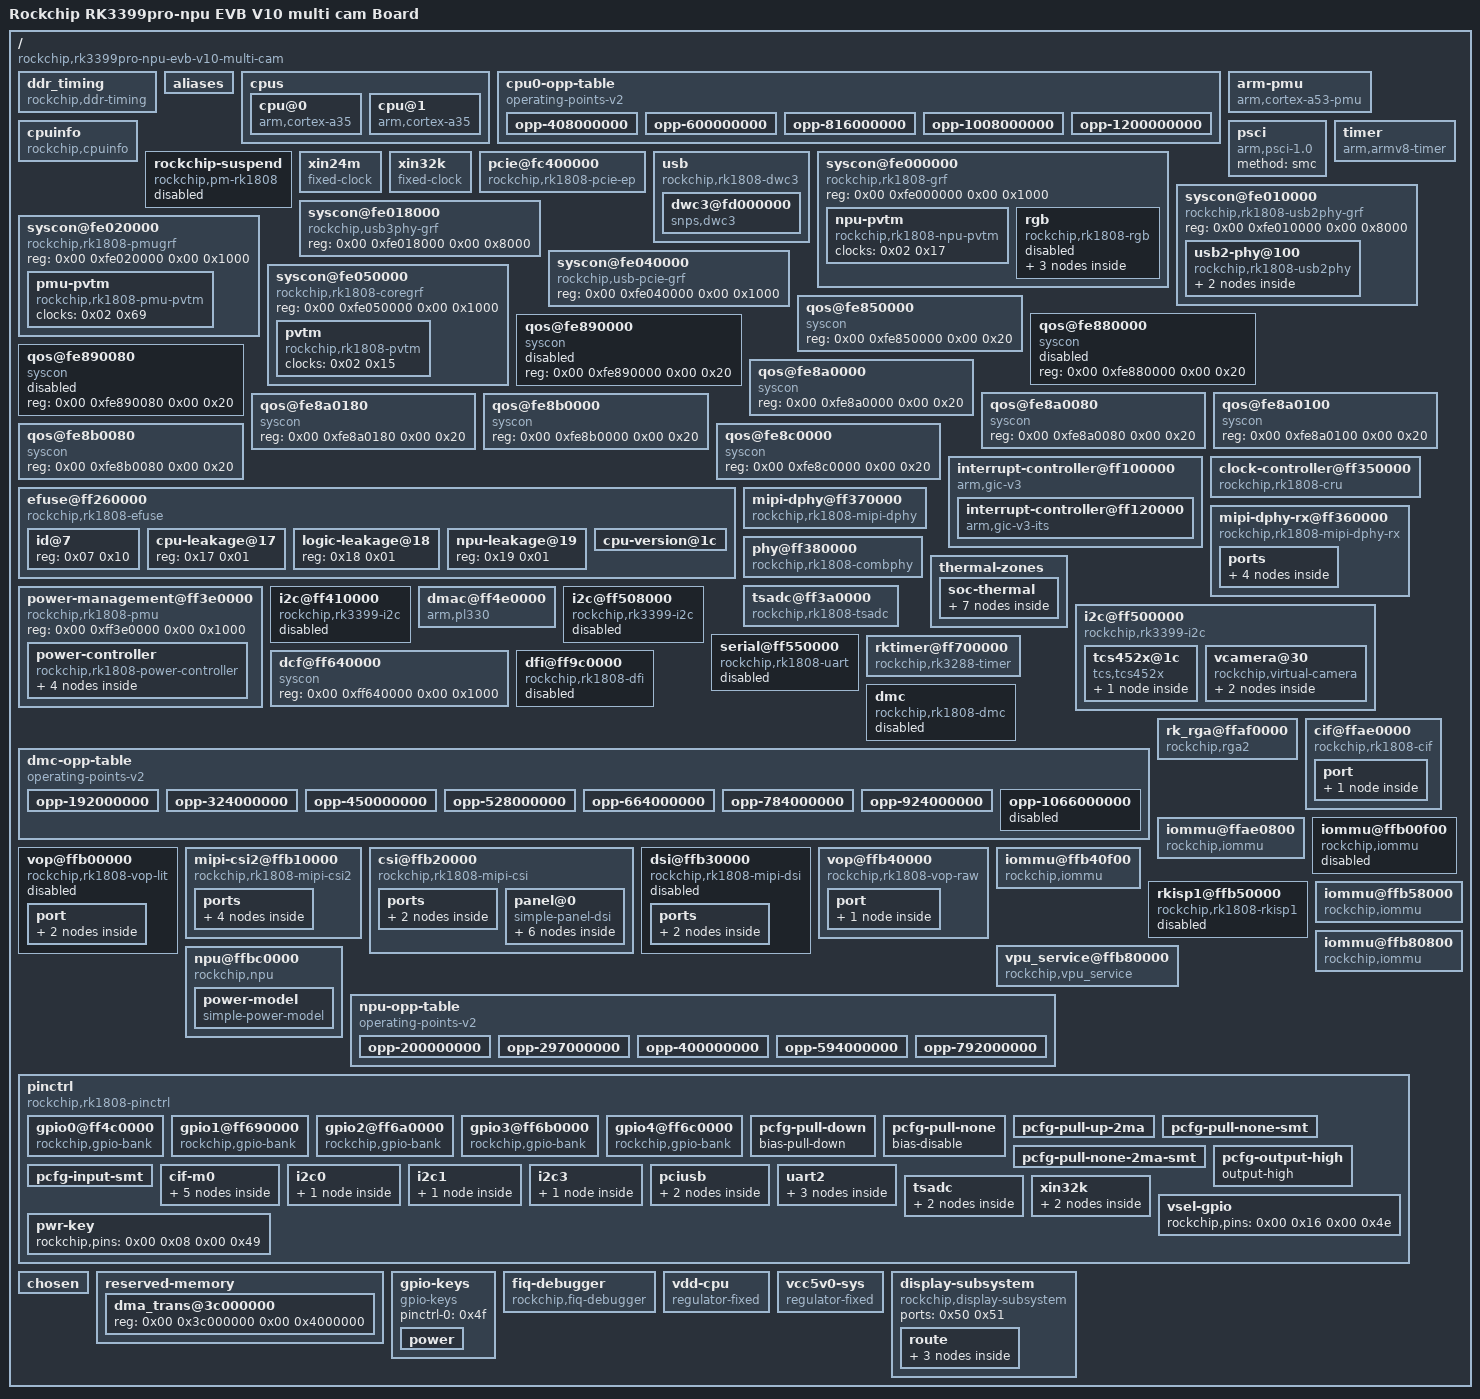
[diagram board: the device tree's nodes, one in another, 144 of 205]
/dts-v1/;

/ {
	compatible = "rockchip,rk3399pro-npu-evb-v10-multi-cam\0rockchip,rk3399pro-npu";
	interrupt-parent = <0x01>;
	#address-cells = <0x02>;
	#size-cells = <0x02>;
	model = "Rockchip RK3399pro-npu EVB V10 multi cam Board";

	ddr_timing {
		compatible = "rockchip,ddr-timing";
		ddr2_speed_bin = <0x00>;
		ddr3_speed_bin = <0x15>;
		ddr4_speed_bin = <0x0c>;
		pd_idle = <0x00>;
		sr_idle = <0x00>;
		sr_mc_gate_idle = <0x00>;
		srpd_lite_idle = <0x00>;
		standby_idle = <0x00>;
		auto_pd_dis_freq = <0x42a>;
		auto_sr_dis_freq = <0x320>;
		ddr2_dll_dis_freq = <0x12c>;
		ddr3_dll_dis_freq = <0x12c>;
		ddr4_dll_dis_freq = <0x271>;
		phy_dll_dis_freq = <0x190>;
		ddr2_odt_dis_freq = <0x64>;
		phy_ddr2_odt_dis_freq = <0x64>;
		ddr2_drv = <0x01>;
		ddr2_odt = <0x96>;
		phy_ddr2_ca_drv = <0x12>;
		phy_ddr2_ck_drv = <0x10>;
		phy_ddr2_dq_drv = <0x12>;
		phy_ddr2_odt = <0x04>;
		ddr3_odt_dis_freq = <0x190>;
		phy_ddr3_odt_dis_freq = <0x190>;
		ddr3_drv = <0x28>;
		ddr3_odt = <0x78>;
		phy_ddr3_ca_drv = <0x12>;
		phy_ddr3_ck_drv = <0x10>;
		phy_ddr3_dq_drv = <0x12>;
		phy_ddr3_odt = <0x04>;
		phy_lpddr2_odt_dis_freq = <0x29a>;
		lpddr2_drv = <0x28>;
		phy_lpddr2_ca_drv = <0x13>;
		phy_lpddr2_ck_drv = <0x11>;
		phy_lpddr2_dq_drv = <0x13>;
		phy_lpddr2_odt = <0x00>;
		lpddr3_odt_dis_freq = <0x190>;
		phy_lpddr3_odt_dis_freq = <0x190>;
		lpddr3_drv = <0x28>;
		lpddr3_odt = <0xf0>;
		phy_lpddr3_ca_drv = <0x13>;
		phy_lpddr3_ck_drv = <0x11>;
		phy_lpddr3_dq_drv = <0x13>;
		phy_lpddr3_odt = <0x04>;
		lpddr4_odt_dis_freq = <0x320>;
		phy_lpddr4_odt_dis_freq = <0x320>;
		lpddr4_drv = <0x3c>;
		lpddr4_dq_odt = <0x28>;
		lpddr4_ca_odt = <0x28>;
		phy_lpddr4_ca_drv = <0x11>;
		phy_lpddr4_ck_cs_drv = <0x05>;
		phy_lpddr4_dq_drv = <0x05>;
		phy_lpddr4_odt = <0x19>;
		ddr4_odt_dis_freq = <0x29a>;
		phy_ddr4_odt_dis_freq = <0x29a>;
		ddr4_drv = <0x22>;
		ddr4_odt = <0xf0>;
		phy_ddr4_ca_drv = <0x13>;
		phy_ddr4_ck_drv = <0x11>;
		phy_ddr4_dq_drv = <0x13>;
		phy_ddr4_odt = <0x04>;
		a0_ddr3a9_de-skew = <0x07>;
		a1_ddr3a14_de-skew = <0x07>;
		a2_ddr3a13_de-skew = <0x07>;
		a3_ddr3a11_de-skew = <0x07>;
		a4_ddr3a2_de-skew = <0x07>;
		a5_ddr3a4_de-skew = <0x07>;
		a6_ddr3a3_de-skew = <0x07>;
		a7_ddr3a6_de-skew = <0x07>;
		a8_ddr3a5_de-skew = <0x07>;
		a9_ddr3a1_de-skew = <0x07>;
		a10_ddr3a0_de-skew = <0x07>;
		a11_ddr3a7_de-skew = <0x07>;
		a12_ddr3casb_de-skew = <0x07>;
		a13_ddr3a8_de-skew = <0x07>;
		a14_ddr3odt0_de-skew = <0x07>;
		a15_ddr3ba1_de-skew = <0x07>;
		a16_ddr3rasb_de-skew = <0x07>;
		a17_ddr3null_de-skew = <0x07>;
		ba0_ddr3ba2_de-skew = <0x07>;
		ba1_ddr3a12_de-skew = <0x07>;
		bg0_ddr3ba0_de-skew = <0x07>;
		bg1_ddr3web_de-skew = <0x07>;
		cke_ddr3cke_de-skew = <0x07>;
		ck_ddr3ck_de-skew = <0x07>;
		ckb_ddr3ckb_de-skew = <0x07>;
		csb0_ddr3a10_de-skew = <0x07>;
		odt0_ddr3a15_de-skew = <0x07>;
		resetn_ddr3resetn_de-skew = <0x07>;
		actn_ddr3csb0_de-skew = <0x07>;
		csb1_ddr3csb1_de-skew = <0x07>;
		odt1_ddr3odt1_de-skew = <0x07>;
		cs0_dm0_rx_de-skew = <0x07>;
		cs0_dm0_tx_de-skew = <0x07>;
		cs0_dq0_rx_de-skew = <0x07>;
		cs0_dq0_tx_de-skew = <0x07>;
		cs0_dq1_rx_de-skew = <0x07>;
		cs0_dq1_tx_de-skew = <0x07>;
		cs0_dq2_rx_de-skew = <0x07>;
		cs0_dq2_tx_de-skew = <0x07>;
		cs0_dq3_rx_de-skew = <0x07>;
		cs0_dq3_tx_de-skew = <0x07>;
		cs0_dq4_rx_de-skew = <0x07>;
		cs0_dq4_tx_de-skew = <0x07>;
		cs0_dq5_rx_de-skew = <0x07>;
		cs0_dq5_tx_de-skew = <0x07>;
		cs0_dq6_rx_de-skew = <0x07>;
		cs0_dq6_tx_de-skew = <0x07>;
		cs0_dq7_rx_de-skew = <0x07>;
		cs0_dq7_tx_de-skew = <0x07>;
		cs0_dqs0p_rx_de-skew = <0x0e>;
		cs0_dqs0p_tx_de-skew = <0x09>;
		cs0_dqs0n_tx_de-skew = <0x09>;
		cs0_dm1_rx_de-skew = <0x07>;
		cs0_dm1_tx_de-skew = <0x07>;
		cs0_dq8_rx_de-skew = <0x07>;
		cs0_dq8_tx_de-skew = <0x07>;
		cs0_dq9_rx_de-skew = <0x07>;
		cs0_dq9_tx_de-skew = <0x07>;
		cs0_dq10_rx_de-skew = <0x07>;
		cs0_dq10_tx_de-skew = <0x07>;
		cs0_dq11_rx_de-skew = <0x07>;
		cs0_dq11_tx_de-skew = <0x07>;
		cs0_dq12_rx_de-skew = <0x07>;
		cs0_dq12_tx_de-skew = <0x07>;
		cs0_dq13_rx_de-skew = <0x07>;
		cs0_dq13_tx_de-skew = <0x07>;
		cs0_dq14_rx_de-skew = <0x07>;
		cs0_dq14_tx_de-skew = <0x07>;
		cs0_dq15_rx_de-skew = <0x07>;
		cs0_dq15_tx_de-skew = <0x07>;
		cs0_dqs1p_rx_de-skew = <0x0e>;
		cs0_dqs1p_tx_de-skew = <0x09>;
		cs0_dqs1n_tx_de-skew = <0x09>;
		cs0_dqs0n_rx_de-skew = <0x0e>;
		cs0_dqs1n_rx_de-skew = <0x0e>;
		cs0_dm2_rx_de-skew = <0x07>;
		cs0_dm2_tx_de-skew = <0x07>;
		cs0_dq16_rx_de-skew = <0x07>;
		cs0_dq16_tx_de-skew = <0x07>;
		cs0_dq17_rx_de-skew = <0x07>;
		cs0_dq17_tx_de-skew = <0x07>;
		cs0_dq18_rx_de-skew = <0x07>;
		cs0_dq18_tx_de-skew = <0x07>;
		cs0_dq19_rx_de-skew = <0x07>;
		cs0_dq19_tx_de-skew = <0x07>;
		cs0_dq20_rx_de-skew = <0x07>;
		cs0_dq20_tx_de-skew = <0x07>;
		cs0_dq21_rx_de-skew = <0x07>;
		cs0_dq21_tx_de-skew = <0x07>;
		cs0_dq22_rx_de-skew = <0x07>;
		cs0_dq22_tx_de-skew = <0x07>;
		cs0_dq23_rx_de-skew = <0x07>;
		cs0_dq23_tx_de-skew = <0x07>;
		cs0_dqs2p_rx_de-skew = <0x0e>;
		cs0_dqs2p_tx_de-skew = <0x09>;
		cs0_dqs2n_tx_de-skew = <0x09>;
		cs0_dm3_rx_de-skew = <0x07>;
		cs0_dm3_tx_de-skew = <0x07>;
		cs0_dq24_rx_de-skew = <0x07>;
		cs0_dq24_tx_de-skew = <0x07>;
		cs0_dq25_rx_de-skew = <0x07>;
		cs0_dq25_tx_de-skew = <0x07>;
		cs0_dq26_rx_de-skew = <0x07>;
		cs0_dq26_tx_de-skew = <0x07>;
		cs0_dq27_rx_de-skew = <0x07>;
		cs0_dq27_tx_de-skew = <0x07>;
		cs0_dq28_rx_de-skew = <0x07>;
		cs0_dq28_tx_de-skew = <0x07>;
		cs0_dq29_rx_de-skew = <0x07>;
		cs0_dq29_tx_de-skew = <0x07>;
		cs0_dq30_rx_de-skew = <0x07>;
		cs0_dq30_tx_de-skew = <0x07>;
		cs0_dq31_rx_de-skew = <0x07>;
		cs0_dq31_tx_de-skew = <0x07>;
		cs0_dqs3p_rx_de-skew = <0x0e>;
		cs0_dqs3p_tx_de-skew = <0x09>;
		cs0_dqs3n_tx_de-skew = <0x09>;
		cs0_dqs2n_rx_de-skew = <0x0e>;
		cs0_dqs3n_rx_de-skew = <0x0e>;
		cs1_dm0_rx_de-skew = <0x07>;
		cs1_dm0_tx_de-skew = <0x07>;
		cs1_dq0_rx_de-skew = <0x07>;
		cs1_dq0_tx_de-skew = <0x07>;
		cs1_dq1_rx_de-skew = <0x07>;
		cs1_dq1_tx_de-skew = <0x07>;
		cs1_dq2_rx_de-skew = <0x07>;
		cs1_dq2_tx_de-skew = <0x07>;
		cs1_dq3_rx_de-skew = <0x07>;
		cs1_dq3_tx_de-skew = <0x07>;
		cs1_dq4_rx_de-skew = <0x07>;
		cs1_dq4_tx_de-skew = <0x07>;
		cs1_dq5_rx_de-skew = <0x07>;
		cs1_dq5_tx_de-skew = <0x07>;
		cs1_dq6_rx_de-skew = <0x07>;
		cs1_dq6_tx_de-skew = <0x07>;
		cs1_dq7_rx_de-skew = <0x07>;
		cs1_dq7_tx_de-skew = <0x07>;
		cs1_dqs0p_rx_de-skew = <0x0e>;
		cs1_dqs0p_tx_de-skew = <0x09>;
		cs1_dqs0n_tx_de-skew = <0x09>;
		cs1_dm1_rx_de-skew = <0x07>;
		cs1_dm1_tx_de-skew = <0x07>;
		cs1_dq8_rx_de-skew = <0x07>;
		cs1_dq8_tx_de-skew = <0x07>;
		cs1_dq9_rx_de-skew = <0x07>;
		cs1_dq9_tx_de-skew = <0x07>;
		cs1_dq10_rx_de-skew = <0x07>;
		cs1_dq10_tx_de-skew = <0x07>;
		cs1_dq11_rx_de-skew = <0x07>;
		cs1_dq11_tx_de-skew = <0x07>;
		cs1_dq12_rx_de-skew = <0x07>;
		cs1_dq12_tx_de-skew = <0x07>;
		cs1_dq13_rx_de-skew = <0x07>;
		cs1_dq13_tx_de-skew = <0x07>;
		cs1_dq14_rx_de-skew = <0x07>;
		cs1_dq14_tx_de-skew = <0x07>;
		cs1_dq15_rx_de-skew = <0x07>;
		cs1_dq15_tx_de-skew = <0x07>;
		cs1_dqs1p_rx_de-skew = <0x0e>;
		cs1_dqs1p_tx_de-skew = <0x09>;
		cs1_dqs1n_tx_de-skew = <0x09>;
		cs1_dqs0n_rx_de-skew = <0x0e>;
		cs1_dqs1n_rx_de-skew = <0x0e>;
		cs1_dm2_rx_de-skew = <0x07>;
		cs1_dm2_tx_de-skew = <0x07>;
		cs1_dq16_rx_de-skew = <0x07>;
		cs1_dq16_tx_de-skew = <0x07>;
		cs1_dq17_rx_de-skew = <0x07>;
		cs1_dq17_tx_de-skew = <0x07>;
		cs1_dq18_rx_de-skew = <0x07>;
		cs1_dq18_tx_de-skew = <0x07>;
		cs1_dq19_rx_de-skew = <0x07>;
		cs1_dq19_tx_de-skew = <0x07>;
		cs1_dq20_rx_de-skew = <0x07>;
		cs1_dq20_tx_de-skew = <0x07>;
		cs1_dq21_rx_de-skew = <0x07>;
		cs1_dq21_tx_de-skew = <0x07>;
		cs1_dq22_rx_de-skew = <0x07>;
		cs1_dq22_tx_de-skew = <0x07>;
		cs1_dq23_rx_de-skew = <0x07>;
		cs1_dq23_tx_de-skew = <0x07>;
		cs1_dqs2p_rx_de-skew = <0x0e>;
		cs1_dqs2p_tx_de-skew = <0x09>;
		cs1_dqs2n_tx_de-skew = <0x09>;
		cs1_dm3_rx_de-skew = <0x07>;
		cs1_dm3_tx_de-skew = <0x07>;
		cs1_dq24_rx_de-skew = <0x07>;
		cs1_dq24_tx_de-skew = <0x07>;
		cs1_dq25_rx_de-skew = <0x07>;
		cs1_dq25_tx_de-skew = <0x07>;
		cs1_dq26_rx_de-skew = <0x07>;
		cs1_dq26_tx_de-skew = <0x07>;
		cs1_dq27_rx_de-skew = <0x07>;
		cs1_dq27_tx_de-skew = <0x07>;
		cs1_dq28_rx_de-skew = <0x07>;
		cs1_dq28_tx_de-skew = <0x07>;
		cs1_dq29_rx_de-skew = <0x07>;
		cs1_dq29_tx_de-skew = <0x07>;
		cs1_dq30_rx_de-skew = <0x07>;
		cs1_dq30_tx_de-skew = <0x07>;
		cs1_dq31_rx_de-skew = <0x07>;
		cs1_dq31_tx_de-skew = <0x07>;
		cs1_dqs3p_rx_de-skew = <0x0e>;
		cs1_dqs3p_tx_de-skew = <0x09>;
		cs1_dqs3n_tx_de-skew = <0x09>;
		cs1_dqs2n_rx_de-skew = <0x0e>;
		cs1_dqs3n_rx_de-skew = <0x0e>;
		phandle = <0x35>;
	};

	aliases {
		i2c0 = "/i2c@ff410000";
		i2c1 = "/i2c@ff500000";
		i2c3 = "/i2c@ff508000";
		serial2 = "/serial@ff550000";
	};

	cpus {
		#address-cells = <0x02>;
		#size-cells = <0x00>;

		cpu@0 {
			device_type = "cpu";
			compatible = "arm,cortex-a35\0arm,armv8";
			reg = <0x00 0x00>;
			enable-method = "psci";
			clocks = <0x02 0x07>;
			operating-points-v2 = <0x03>;
			dynamic-power-coefficient = <0x4a>;
			#cooling-cells = <0x02>;
			cpu-supply = <0x04>;
			phandle = <0x06>;
		};

		cpu@1 {
			device_type = "cpu";
			compatible = "arm,cortex-a35\0arm,armv8";
			reg = <0x00 0x01>;
			enable-method = "psci";
			clocks = <0x02 0x07>;
			operating-points-v2 = <0x03>;
			dynamic-power-coefficient = <0x4a>;
			cpu-supply = <0x04>;
			phandle = <0x07>;
		};
	};

	cpu0-opp-table {
		compatible = "operating-points-v2";
		opp-shared;
		nvmem-cells = <0x05>;
		nvmem-cell-names = "leakage";
		phandle = <0x03>;

		opp-408000000 {
			opp-hz = <0x00 0x18519600>;
			opp-microvolt = <0xb71b0 0xb71b0 0xe7ef0>;
			clock-latency-ns = <0x9c40>;
			opp-suspend;
		};

		opp-600000000 {
			opp-hz = <0x00 0x23c34600>;
			opp-microvolt = <0xb71b0 0xb71b0 0xe7ef0>;
			clock-latency-ns = <0x9c40>;
		};

		opp-816000000 {
			opp-hz = <0x00 0x30a32c00>;
			opp-microvolt = <0xb71b0 0xb71b0 0xe7ef0>;
			clock-latency-ns = <0x9c40>;
		};

		opp-1008000000 {
			opp-hz = <0x00 0x3c14dc00>;
			opp-microvolt = <0xb71b0 0xb71b0 0xe7ef0>;
			clock-latency-ns = <0x9c40>;
		};

		opp-1200000000 {
			opp-hz = <0x00 0x47868c00>;
			opp-microvolt = <0xb71b0 0xb71b0 0xe7ef0>;
			clock-latency-ns = <0x9c40>;
		};
	};

	arm-pmu {
		compatible = "arm,cortex-a53-pmu";
		interrupts = <0x00 0xe4 0x04 0x00 0xe5 0x04>;
		interrupt-affinity = <0x06 0x07>;
	};

	cpuinfo {
		compatible = "rockchip,cpuinfo";
		nvmem-cells = <0x08 0x09>;
		nvmem-cell-names = "id\0cpu-version";
	};

	psci {
		compatible = "arm,psci-1.0";
		method = "smc";
	};

	rockchip-suspend {
		compatible = "rockchip,pm-rk1808";
		status = "disabled";
		rockchip,sleep-debug-en = <0x00>;
		rockchip,sleep-mode-config = <0x1000602>;
		rockchip,wakeup-config = <0x04>;
		phandle = <0x52>;
	};

	timer {
		compatible = "arm,armv8-timer";
		interrupts = <0x01 0x0d 0x08 0x01 0x0e 0x08 0x01 0x0b 0x08 0x01 0x0a 0x08>;
		arm,no-tick-in-suspend;
	};

	xin24m {
		compatible = "fixed-clock";
		clock-frequency = <0x16e3600>;
		clock-output-names = "xin24m";
		#clock-cells = <0x00>;
		phandle = <0x53>;
	};

	xin32k {
		compatible = "fixed-clock";
		clock-frequency = <0x8000>;
		clock-output-names = "xin32k";
		#clock-cells = <0x00>;
		pinctrl-names = "default";
		pinctrl-0 = <0x0a>;
		phandle = <0x54>;
	};

	pcie@fc400000 {
		compatible = "rockchip,rk1808-pcie-ep\0snps,dw-pcie";
		#address-cells = <0x03>;
		#size-cells = <0x02>;
		bus-range = <0x00 0x1f>;
		clocks = <0x02 0xa4 0x02 0xce 0x02 0xa6 0x02 0xfe 0x02 0x20>;
		clock-names = "hsclk\0lsclk\0aclk\0pclk\0sclk-aux";
		interrupts = <0x00 0x56 0x04 0x00 0x57 0x04 0x00 0x58 0x04 0x00 0x59 0x04>;
		interrupt-names = "sys\0legacy\0msg\0err";
		linux,pci-domain = <0x00>;
		num-ib-windows = <0x06>;
		num-ob-windows = <0x02>;
		msi-map = <0x00 0x0b 0x00 0x1000>;
		num-lanes = <0x02>;
		phys = <0x0c 0x02>;
		phy-names = "pcie-phy";
		pinctrl-names = "default";
		pinctrl-0 = <0x0d>;
		power-domains = <0x0e 0x06>;
		ranges = <0x800 0x00 0xf8000000 0x00 0xf8000000 0x00 0x800000 0x83000000 0x00 0xf8800000 0x00 0xf8800000 0x00 0x3700000 0x81000000 0x00 0xfbf00000 0x00 0xfbf00000 0x00 0x100000>;
		reg = <0x00 0xfc000000 0x00 0x400000 0x00 0xfc400000 0x00 0x10000>;
		reg-names = "pcie-dbi\0pcie-apb";
		resets = <0x02 0x30 0x02 0x31 0x02 0x32 0x02 0x33 0x02 0x34 0x02 0x35 0x02 0x36 0x02 0x37 0x02 0x38 0x02 0x39 0x02 0x3a 0x02 0x3b 0x02 0x3c 0x02 0x3d 0x02 0x3e 0x02 0x3f 0x02 0x40 0x02 0x41 0x02 0x42>;
		reset-names = "niu-h\0niu-l\0grf-p\0ctl-p\0ctl-powerup\0ctl-mst-a\0ctl-slv-a\0ctl-dbi-a\0ctl-button\0ctl-pe\0ctl-core\0ctl-nsticky\0ctl-sticky\0ctl-pwr\0ctl-niu-a\0ctl-niu-p\0phy-por\0phy-p\0phy-pipe";
		rockchip,usbpciegrf = <0x0f>;
		rockchip,pmugrf = <0x10>;
		status = "okay";
		memory-region = <0x11>;
		busno = <0x01>;
		phandle = <0x55>;
	};

	usb {
		compatible = "rockchip,rk1808-dwc3\0rockchip,rk3399-dwc3";
		clocks = <0x02 0x21 0x02 0xa5 0x02 0x22>;
		clock-names = "ref_clk\0bus_clk\0suspend_clk";
		assigned-clocks = <0x02 0x22>;
		assigned-clock-rates = <0x16e3600>;
		power-domains = <0x0e 0x06>;
		resets = <0x02 0x48>;
		reset-names = "usb3-otg";
		#address-cells = <0x02>;
		#size-cells = <0x02>;
		ranges;
		status = "okay";
		extcon = <0x12>;
		phandle = <0x56>;

		dwc3@fd000000 {
			compatible = "snps,dwc3";
			reg = <0x00 0xfd000000 0x00 0x200000>;
			interrupts = <0x00 0x4b 0x04>;
			dr_mode = "peripheral";
			phys = <0x13>;
			phy-names = "usb2-phy";
			phy_type = "utmi_wide";
			snps,dis_enblslpm_quirk;
			snps,dis-u1u2-quirk;
			snps,dis-u2-freeclk-exists-quirk;
			snps,dis_u2_susphy_quirk;
			snps,dis_u3_susphy_quirk;
			snps,dis-del-phy-power-chg-quirk;
			snps,tx-ipgap-linecheck-dis-quirk;
			snps,xhci-trb-ent-quirk;
			status = "okay";
			maximum-speed = "high-speed";
			phandle = <0x57>;
		};
	};

	syscon@fe000000 {
		compatible = "rockchip,rk1808-grf\0syscon\0simple-mfd";
		reg = <0x00 0xfe000000 0x00 0x1000>;
		#address-cells = <0x01>;
		#size-cells = <0x01>;
		phandle = <0x15>;

		npu-pvtm {
			compatible = "rockchip,rk1808-npu-pvtm";
			clocks = <0x02 0x17>;
			clock-names = "npu";
			status = "okay";
			phandle = <0x58>;
		};

		rgb {
			compatible = "rockchip,rk1808-rgb";
			status = "disabled";
			phandle = <0x59>;

			ports {
				#address-cells = <0x01>;
				#size-cells = <0x00>;

				port@0 {
					reg = <0x00>;

					endpoint {
						remote-endpoint = <0x14>;
						phandle = <0x3b>;
					};
				};
			};
		};
	};

	syscon@fe010000 {
		compatible = "rockchip,rk1808-usb2phy-grf\0syscon\0simple-mfd";
		reg = <0x00 0xfe010000 0x00 0x8000>;
		#address-cells = <0x01>;
		#size-cells = <0x01>;
		phandle = <0x5a>;

		usb2-phy@100 {
			compatible = "rockchip,rk1808-usb2phy";
			reg = <0x100 0x10>;
			clocks = <0x02 0x6d>;
			clock-names = "phyclk";
			#clock-cells = <0x00>;
			assigned-clocks = <0x02 0x14>;
			assigned-clock-parents = <0x12>;
			clock-output-names = "usb480m_phy";
			status = "okay";
			phandle = <0x12>;

			host-port {
				#phy-cells = <0x00>;
				interrupts = <0x00 0x4f 0x04>;
				interrupt-names = "linestate";
				status = "disabled";
				phandle = <0x5b>;
			};

			otg-port {
				#phy-cells = <0x00>;
				interrupts = <0x00 0x4e 0x04 0x00 0x4d 0x04 0x00 0x4c 0x04>;
				interrupt-names = "otg-bvalid\0otg-id\0linestate";
				status = "okay";
				phandle = <0x13>;
			};
		};
	};

	syscon@fe018000 {
		compatible = "rockchip,usb3phy-grf\0syscon";
		reg = <0x00 0xfe018000 0x00 0x8000>;
		phandle = <0x18>;
	};

	syscon@fe020000 {
		compatible = "rockchip,rk1808-pmugrf\0syscon\0simple-mfd";
		reg = <0x00 0xfe020000 0x00 0x1000>;
		#address-cells = <0x01>;
		#size-cells = <0x01>;
		phandle = <0x10>;

		pmu-pvtm {
			compatible = "rockchip,rk1808-pmu-pvtm";
			clocks = <0x02 0x69>;
			clock-names = "pmu";
			status = "okay";
			phandle = <0x5c>;
		};
	};

	syscon@fe040000 {
		compatible = "rockchip,usb-pcie-grf\0syscon";
		reg = <0x00 0xfe040000 0x00 0x1000>;
		phandle = <0x0f>;
	};

	syscon@fe050000 {
		compatible = "rockchip,rk1808-coregrf\0syscon\0simple-mfd";
		reg = <0x00 0xfe050000 0x00 0x1000>;
		#address-cells = <0x01>;
		#size-cells = <0x01>;
		phandle = <0x5d>;

		pvtm {
			compatible = "rockchip,rk1808-pvtm";
			clocks = <0x02 0x15>;
			clock-names = "core";
			status = "okay";
			phandle = <0x5e>;
		};
	};

	qos@fe850000 {
		compatible = "syscon";
		reg = <0x00 0xfe850000 0x00 0x20>;
		phandle = <0x1e>;
	};

	qos@fe880000 {
		compatible = "syscon";
		reg = <0x00 0xfe880000 0x00 0x20>;
		status = "disabled";
		phandle = <0x1f>;
	};

	qos@fe890000 {
		compatible = "syscon";
		reg = <0x00 0xfe890000 0x00 0x20>;
		status = "disabled";
		phandle = <0x20>;
	};

	qos@fe890080 {
		compatible = "syscon";
		reg = <0x00 0xfe890080 0x00 0x20>;
		status = "disabled";
		phandle = <0x21>;
	};

	qos@fe8a0000 {
		compatible = "syscon";
		reg = <0x00 0xfe8a0000 0x00 0x20>;
		phandle = <0x25>;
	};

	qos@fe8a0080 {
		compatible = "syscon";
		reg = <0x00 0xfe8a0080 0x00 0x20>;
		phandle = <0x23>;
	};

	qos@fe8a0100 {
		compatible = "syscon";
		reg = <0x00 0xfe8a0100 0x00 0x20>;
		phandle = <0x24>;
	};

	qos@fe8a0180 {
		compatible = "syscon";
		reg = <0x00 0xfe8a0180 0x00 0x20>;
		phandle = <0x26>;
	};

	qos@fe8b0000 {
		compatible = "syscon";
		reg = <0x00 0xfe8b0000 0x00 0x20>;
		phandle = <0x27>;
	};

	qos@fe8b0080 {
		compatible = "syscon";
		reg = <0x00 0xfe8b0080 0x00 0x20>;
		phandle = <0x28>;
	};

	qos@fe8c0000 {
		compatible = "syscon";
		reg = <0x00 0xfe8c0000 0x00 0x20>;
		phandle = <0x22>;
	};

	interrupt-controller@ff100000 {
		compatible = "arm,gic-v3";
		#interrupt-cells = <0x03>;
		#address-cells = <0x02>;
		#size-cells = <0x02>;
		ranges;
		interrupt-controller;
		reg = <0x00 0xff100000 0x00 0x10000 0x00 0xff140000 0x00 0xc0000 0x00 0xff300000 0x00 0x10000 0x00 0xff310000 0x00 0x10000 0x00 0xff320000 0x00 0x10000>;
		interrupts = <0x01 0x09 0x04>;
		phandle = <0x01>;

		interrupt-controller@ff120000 {
			compatible = "arm,gic-v3-its";
			msi-controller;
			reg = <0x00 0xff120000 0x00 0x20000>;
			phandle = <0x0b>;
		};
	};

	efuse@ff260000 {
		compatible = "rockchip,rk1808-efuse";
		reg = <0x00 0xff3b0000 0x00 0x50>;
		#address-cells = <0x01>;
		#size-cells = <0x01>;
		clocks = <0x02 0x4f 0x02 0x113>;
		clock-names = "sclk_efuse\0pclk_efuse";
		assigned-clocks = <0x02 0x4f>;
		assigned-clock-rates = <0x16e3600>;
		rockchip,efuse-size = <0x20>;
		phandle = <0x5f>;

		id@7 {
			reg = <0x07 0x10>;
			phandle = <0x08>;
		};

		cpu-leakage@17 {
			reg = <0x17 0x01>;
			phandle = <0x05>;
		};

		logic-leakage@18 {
			reg = <0x18 0x01>;
			phandle = <0x36>;
		};

		npu-leakage@19 {
			reg = <0x19 0x01>;
			phandle = <0x48>;
		};

		cpu-version@1c {
			reg = <0x1c 0x01>;
			bits = <0x03 0x03>;
			phandle = <0x09>;
		};
	};

	clock-controller@ff350000 {
		compatible = "rockchip,rk1808-cru";
		reg = <0x00 0xff350000 0x00 0x5000>;
		rockchip,grf = <0x15>;
		#clock-cells = <0x01>;
		#reset-cells = <0x01>;
		assigned-clocks = <0x02 0x04 0x02 0x03 0x02 0x06 0x02 0x07 0x02 0xa9 0x02 0xd0 0x02 0xab 0x02 0xd5 0x02 0x100>;
		assigned-clock-rates = <0x46cf7100 0x3b9aca00 0x5f5e100 0x47868c00 0xbebc200 0x5f5e100 0x11e1a300 0xbebc200 0x5f5e100>;
		phandle = <0x02>;
	};

	mipi-dphy-rx@ff360000 {
		compatible = "rockchip,rk1808-mipi-dphy-rx";
		reg = <0x00 0xff360000 0x00 0x4000>;
		clocks = <0x02 0x11e>;
		clock-names = "pclk";
		power-domains = <0x0e 0x08>;
		rockchip,grf = <0x15>;
		status = "okay";
		phandle = <0x60>;

		ports {
			#address-cells = <0x01>;
			#size-cells = <0x00>;

			port@0 {
				reg = <0x00>;
				#address-cells = <0x01>;
				#size-cells = <0x00>;

				endpoint@1 {
					reg = <0x01>;
					remote-endpoint = <0x16>;
					data-lanes = <0x01 0x02 0x03 0x04>;
					phandle = <0x2e>;
				};
			};

			port@1 {
				reg = <0x01>;
				#address-cells = <0x01>;
				#size-cells = <0x00>;

				endpoint@0 {
					reg = <0x00>;
					remote-endpoint = <0x17>;
					phandle = <0x3c>;
				};
			};
		};
	};

	mipi-dphy@ff370000 {
		compatible = "rockchip,rk1808-mipi-dphy";
		reg = <0x00 0xff370000 0x00 0x500>;
		clocks = <0x02 0x6e 0x02 0x11d>;
		clock-names = "ref\0pclk";
		clock-output-names = "mipi_dphy_pll";
		#clock-cells = <0x00>;
		resets = <0x02 0x7d>;
		reset-names = "apb";
		#phy-cells = <0x00>;
		rockchip,grf = <0x15>;
		status = "okay";
		phandle = <0x3e>;
	};

	phy@ff380000 {
		compatible = "rockchip,rk1808-combphy";
		reg = <0x00 0xff380000 0x00 0x10000>;
		#phy-cells = <0x01>;
		clocks = <0x02 0x6f>;
		clock-names = "refclk";
		assigned-clocks = <0x02 0x6f>;
		assigned-clock-rates = <0x17d7840>;
		resets = <0x02 0x48 0x02 0x40 0x02 0x41 0x02 0x42>;
		reset-names = "otg-rst\0combphy-por\0combphy-apb\0combphy-pipe";
		rockchip,combphygrf = <0x18>;
		rockchip,usbpciegrf = <0x0f>;
		status = "okay";
		phandle = <0x0c>;
	};

	thermal-zones {
		phandle = <0x61>;

		soc-thermal {
			polling-delay-passive = <0x14>;
			polling-delay = <0x3e8>;
			sustainable-power = <0x20f>;
			thermal-sensors = <0x19 0x00>;
			phandle = <0x62>;

			trips {

				trip-point-0 {
					temperature = <0x124f8>;
					hysteresis = <0x7d0>;
					type = "passive";
					phandle = <0x63>;
				};

				trip-point-1 {
					temperature = <0x14c08>;
					hysteresis = <0x7d0>;
					type = "passive";
					phandle = <0x1a>;
				};

				soc-crit {
					temperature = <0x1c138>;
					hysteresis = <0x7d0>;
					type = "critical";
					phandle = <0x64>;
				};
			};

			cooling-maps {

				map0 {
					trip = <0x1a>;
					cooling-device = <0x06 0xffffffff 0xffffffff>;
					contribution = <0x1000>;
				};

				map1 {
					trip = <0x1a>;
					cooling-device = <0x1b 0xffffffff 0xffffffff>;
					contribution = <0x400>;
				};
			};
		};
	};

	tsadc@ff3a0000 {
		compatible = "rockchip,rk1808-tsadc";
		reg = <0x00 0xff3a0000 0x00 0x100>;
		interrupts = <0x00 0x20 0x04>;
		rockchip,grf = <0x15>;
		clocks = <0x02 0x4c 0x02 0x111>;
		clock-names = "tsadc\0apb_pclk";
		assigned-clocks = <0x02 0x4c>;
		assigned-clock-rates = <0x9eb10>;
		resets = <0x02 0xff>;
		reset-names = "tsadc-apb";
		#thermal-sensor-cells = <0x01>;
		rockchip,hw-tshut-temp = <0x1d4c0>;
		status = "okay";
		rockchip,hw-tshut-mode = <0x01>;
		rockchip,hw-tshut-polarity = <0x01>;
		pinctrl-names = "init\0default";
		pinctrl-0 = <0x1c>;
		pinctrl-1 = <0x1d>;
		phandle = <0x19>;
	};

	power-management@ff3e0000 {
		compatible = "rockchip,rk1808-pmu\0syscon\0simple-mfd";
		reg = <0x00 0xff3e0000 0x00 0x1000>;
		phandle = <0x65>;

		power-controller {
			compatible = "rockchip,rk1808-power-controller";
			#power-domain-cells = <0x01>;
			#address-cells = <0x01>;
			#size-cells = <0x00>;
			status = "okay";
			phandle = <0x0e>;

			pd_npu@4 {
				reg = <0x04>;
				clocks = <0x02 0x16 0x02 0x94 0x02 0xc7>;
				pm_qos = <0x1e>;
			};

			pd_pcie@6 {
				reg = <0x06>;
				clocks = <0x02 0xa4 0x02 0xce 0x02 0xa6 0x02 0xa7 0x02 0xa8 0x02 0xfe 0x02 0x20 0x02 0x20 0x02 0xa5 0x02 0xcf 0x02 0xde 0x02 0x21 0x02 0x22>;
				pm_qos = <0x1f 0x20 0x21>;
			};

			pd_vpu@7 {
				reg = <0x07>;
				clocks = <0x02 0x93 0x02 0xc8>;
				pm_qos = <0x22>;
			};

			pd_vio@8 {
				reg = <0x08>;
				clocks = <0x02 0x9e 0x02 0xc9 0x02 0x9f 0x02 0xca 0x02 0xa0 0x02 0xcb 0x02 0xfb 0x02 0xfc 0x02 0xa1 0x02 0xcc 0x02 0xa2 0x02 0xcd 0x02 0xa3 0x02 0xdf 0x02 0xfd 0x02 0x0a 0x02 0x0b>;
				pm_qos = <0x23 0x24 0x25 0x26 0x27 0x28>;
			};
		};
	};

	i2c@ff410000 {
		compatible = "rockchip,rk3399-i2c";
		reg = <0x00 0xff410000 0x00 0x1000>;
		clocks = <0x02 0x6a 0x02 0x126>;
		clock-names = "i2c\0pclk";
		interrupts = <0x00 0x07 0x04>;
		pinctrl-names = "default";
		pinctrl-0 = <0x29>;
		#address-cells = <0x01>;
		#size-cells = <0x00>;
		status = "disabled";
		phandle = <0x66>;
	};

	dmac@ff4e0000 {
		compatible = "arm,pl330\0arm,primecell";
		reg = <0x00 0xff4e0000 0x00 0x4000>;
		interrupts = <0x00 0x01 0x04>;
		clocks = <0x02 0xae>;
		clock-names = "apb_pclk";
		#dma-cells = <0x01>;
		peripherals-req-type-burst;
		phandle = <0x30>;
	};

	i2c@ff500000 {
		compatible = "rockchip,rk3399-i2c";
		reg = <0x00 0xff500000 0x00 0x1000>;
		clocks = <0x02 0x44 0x02 0x109>;
		clock-names = "i2c\0pclk";
		interrupts = <0x00 0x08 0x04>;
		pinctrl-names = "default";
		pinctrl-0 = <0x2a>;
		#address-cells = <0x01>;
		#size-cells = <0x00>;
		status = "okay";
		phandle = <0x67>;

		tcs452x@1c {
			compatible = "tcs,tcs452x";
			reg = <0x1c>;
			vin-supply = <0x2b>;
			regulator-compatible = "fan53555-reg";
			pinctrl-0 = <0x2c>;
			vsel-gpios = <0x2d 0x16 0x00>;
			regulator-name = "vdd_npu";
			regulator-min-microvolt = <0xb71b0>;
			regulator-max-microvolt = <0xd6d80>;
			regulator-init-microvolt = <0xd6d80>;
			regulator-ramp-delay = <0x8fc>;
			fcs,suspend-voltage-selector = <0x01>;
			regulator-always-on;
			regulator-boot-on;
			regulator-initial-state = <0x03>;
			phandle = <0x47>;

			regulator-state-mem {
				regulator-off-in-suspend;
			};
		};

		vcamera@30 {
			compatible = "rockchip,virtual-camera";
			reg = <0x30>;
			width = <0x500>;
			height = <0x2d0>;
			bus-format = <0x2006>;

			port {

				endpoint {
					remote-endpoint = <0x2e>;
					link-frequencies = <0x00 0x1312d000>;
					phandle = <0x16>;
				};
			};
		};
	};

	i2c@ff508000 {
		compatible = "rockchip,rk3399-i2c";
		reg = <0x00 0xff508000 0x00 0x1000>;
		clocks = <0x02 0x46 0x02 0x10b>;
		clock-names = "i2c\0pclk";
		interrupts = <0x00 0x53 0x04>;
		pinctrl-names = "default";
		pinctrl-0 = <0x2f>;
		#address-cells = <0x01>;
		#size-cells = <0x00>;
		status = "disabled";
		phandle = <0x68>;
	};

	serial@ff550000 {
		compatible = "rockchip,rk1808-uart\0snps,dw-apb-uart";
		reg = <0x00 0xff550000 0x00 0x100>;
		interrupts = <0x00 0x0f 0x04>;
		clocks = <0x02 0x3e 0x02 0x103>;
		clock-names = "baudclk\0apb_pclk";
		reg-shift = <0x02>;
		reg-io-width = <0x04>;
		dmas = <0x30 0x04 0x30 0x05>;
		pinctrl-names = "default";
		pinctrl-0 = <0x31>;
		status = "disabled";
		phandle = <0x69>;
	};

	dcf@ff640000 {
		compatible = "syscon";
		reg = <0x00 0xff640000 0x00 0x1000>;
		phandle = <0x32>;
	};

	rktimer@ff700000 {
		compatible = "rockchip,rk3288-timer";
		reg = <0x00 0xff700000 0x00 0x1000>;
		interrupts = <0x00 0x1a 0x04>;
		clocks = <0x02 0x11b 0x02 0x57>;
		clock-names = "pclk\0timer";
		phandle = <0x6a>;
	};

	dfi@ff9c0000 {
		reg = <0x00 0xff9c0000 0x00 0x400>;
		compatible = "rockchip,rk1808-dfi";
		rockchip,pmugrf = <0x10>;
		status = "disabled";
		phandle = <0x33>;
	};

	dmc {
		compatible = "rockchip,rk1808-dmc";
		dcf_reg = <0x32>;
		interrupts = <0x00 0x00 0x04>;
		interrupt-names = "complete_irq";
		devfreq-events = <0x33>;
		clocks = <0x02 0x18>;
		clock-names = "dmc_clk";
		operating-points-v2 = <0x34>;
		ddr_timing = <0x35>;
		upthreshold = <0x28>;
		downdifferential = <0x14>;
		system-status-freq = <0x01 0xe1960 0x08 0x6ddd0 0x02 0x50140 0x1000 0xe1960 0x4000 0xe1960 0x2000 0xe1960>;
		auto-min-freq = <0x50140>;
		auto-freq-en = <0x00>;
		#cooling-cells = <0x02>;
		status = "disabled";
		phandle = <0x6b>;
	};

	dmc-opp-table {
		compatible = "operating-points-v2";
		rockchip,max-volt = <0xe7ef0>;
		rockchip,evb-irdrop = <0x30d4>;
		nvmem-cells = <0x36>;
		nvmem-cell-names = "leakage";
		phandle = <0x34>;

		opp-192000000 {
			opp-hz = <0x00 0xb71b000>;
			opp-microvolt = <0xb71b0>;
		};

		opp-324000000 {
			opp-hz = <0x00 0x134fd900>;
			opp-microvolt = <0xb71b0>;
		};

		opp-450000000 {
			opp-hz = <0x00 0x1ad27480>;
			opp-microvolt = <0xb71b0>;
		};

		opp-528000000 {
			opp-hz = <0x00 0x1f78a400>;
			opp-microvolt = <0xb71b0>;
		};

		opp-664000000 {
			opp-hz = <0x00 0x2793d600>;
			opp-microvolt = <0xb71b0>;
		};

		opp-784000000 {
			opp-hz = <0x00 0x2ebae400>;
			opp-microvolt = <0xb71b0>;
		};

		opp-924000000 {
			opp-hz = <0x00 0x37131f00>;
			opp-microvolt = <0xb71b0>;
		};

		opp-1066000000 {
			opp-hz = <0x00 0x3f89de80>;
			opp-microvolt = <0xbd358>;
			status = "disabled";
		};
	};

	rk_rga@ffaf0000 {
		compatible = "rockchip,rga2";
		dev_mode = <0x00>;
		reg = <0x00 0xffaf0000 0x00 0x1000>;
		interrupts = <0x00 0x3c 0x04>;
		clocks = <0x02 0xa1 0x02 0xcc 0x02 0x1d>;
		clock-names = "aclk_rga\0hclk_rga\0clk_rga";
		power-domains = <0x0e 0x08>;
		dma-coherent;
		status = "okay";
		phandle = <0x6c>;
	};

	cif@ffae0000 {
		compatible = "rockchip,rk1808-cif";
		reg = <0x00 0xffae0000 0x00 0x200 0x00 0xffb10000 0x00 0x100>;
		reg-names = "cif_regs\0csihost_regs";
		interrupts = <0x00 0x38 0x04 0x00 0x69 0x04 0x00 0x6a 0x04>;
		interrupt-names = "cif-intr\0csi-intr1\0csi-intr2";
		clocks = <0x02 0xa3 0x02 0x0c 0x02 0xdf 0x02 0x1f 0x02 0xfd>;
		clock-names = "aclk_cif\0dclk_cif\0hclk_cif\0sclk_cif_out\0pclk_csi2host";
		resets = <0x02 0x74 0x02 0x75 0x02 0x76 0x02 0x78 0x02 0x77>;
		reset-names = "rst_cif_a\0rst_cif_h\0rst_cif_i\0rst_cif_d\0rst_cif_pclkin";
		power-domains = <0x0e 0x08>;
		iommus = <0x37>;
		status = "okay";
		phandle = <0x6d>;

		port {

			endpoint@0 {
				remote-endpoint = <0x38>;
				data-lanes = <0x01 0x02 0x03 0x04>;
				phandle = <0x3d>;
			};
		};
	};

	iommu@ffae0800 {
		compatible = "rockchip,iommu";
		reg = <0x00 0xffae0800 0x00 0x100>;
		interrupts = <0x00 0x38 0x04>;
		interrupt-names = "cif_mmu";
		clocks = <0x02 0xa3 0x02 0xdf>;
		clock-names = "aclk\0hclk";
		power-domains = <0x0e 0x08>;
		#iommu-cells = <0x00>;
		status = "okay";
		phandle = <0x37>;
	};

	vop@ffb00000 {
		compatible = "rockchip,rk1808-vop-lit";
		reg = <0x00 0xffb00000 0x00 0x200>;
		reg-names = "regs";
		interrupts = <0x00 0x3d 0x04>;
		clocks = <0x02 0xa0 0x02 0x0b 0x02 0xcb>;
		clock-names = "aclk_vop\0dclk_vop\0hclk_vop";
		power-domains = <0x0e 0x08>;
		iommus = <0x39>;
		status = "disabled";
		phandle = <0x6e>;

		port {
			#address-cells = <0x01>;
			#size-cells = <0x00>;
			phandle = <0x50>;

			endpoint@0 {
				reg = <0x00>;
				remote-endpoint = <0x3a>;
				phandle = <0x41>;
			};

			endpoint@1 {
				reg = <0x01>;
				remote-endpoint = <0x3b>;
				phandle = <0x14>;
			};
		};
	};

	iommu@ffb00f00 {
		compatible = "rockchip,iommu";
		reg = <0x00 0xffb00f00 0x00 0x100>;
		interrupts = <0x00 0x3d 0x04>;
		interrupt-names = "vopl_mmu";
		clocks = <0x02 0xa0 0x02 0xcb>;
		clock-names = "aclk\0hclk";
		power-domains = <0x0e 0x08>;
		#iommu-cells = <0x00>;
		status = "disabled";
		phandle = <0x39>;
	};

	mipi-csi2@ffb10000 {
		compatible = "rockchip,rk1808-mipi-csi2";
		reg = <0x00 0xffb10000 0x00 0x100>;
		reg-names = "csihost_regs";
		interrupts = <0x00 0x6a 0x04 0x00 0x69 0x04>;
		interrupt-names = "csi-intr1\0csi-intr2";
		clocks = <0x02 0xfd>;
		clock-names = "pclk_csi2host";
		status = "okay";
		phandle = <0x6f>;

		ports {
			#address-cells = <0x01>;
			#size-cells = <0x00>;

			port@0 {
				reg = <0x00>;
				#address-cells = <0x01>;
				#size-cells = <0x00>;

				endpoint@1 {
					reg = <0x01>;
					remote-endpoint = <0x3c>;
					data-lanes = <0x01 0x02 0x03 0x04>;
					phandle = <0x17>;
				};
			};

			port@1 {
				reg = <0x01>;
				#address-cells = <0x01>;
				#size-cells = <0x00>;

				endpoint@0 {
					reg = <0x00>;
					remote-endpoint = <0x3d>;
					data-lanes = <0x01 0x02 0x03 0x04>;
					phandle = <0x38>;
				};
			};
		};
	};

	csi@ffb20000 {
		compatible = "rockchip,rk1808-mipi-csi";
		reg = <0x00 0xffb20000 0x00 0x500>;
		reg-names = "csi_regs";
		interrupts = <0x00 0x39 0x04>;
		clocks = <0x02 0xfc 0x3e>;
		clock-names = "pclk\0hs_clk";
		resets = <0x02 0x69 0x02 0x6a 0x02 0x6b 0x02 0x6c 0x02 0x6d>;
		reset-names = "tx_apb\0tx_bytehs\0tx_esc\0tx_cam\0tx_i";
		phys = <0x3e>;
		phy-names = "mipi_dphy";
		power-domains = <0x0e 0x08>;
		rockchip,grf = <0x15>;
		#address-cells = <0x01>;
		#size-cells = <0x00>;
		status = "okay";
		phandle = <0x70>;

		ports {

			port {

				endpoint {
					remote-endpoint = <0x3f>;
					phandle = <0x43>;
				};
			};
		};

		panel@0 {
			compatible = "simple-panel-dsi";
			reg = <0x00>;
			dsi,flags = <0xe03>;
			dsi,format = <0x13>;
			dsi,lanes = <0x04>;

			display-timings {
				native-mode = <0x40>;

				timing-1280x3-720 {
					clock-frequency = <0x4c4b400>;
					hactive = <0xf00>;
					vactive = <0x2d0>;
					hfront-porch = <0x4b0>;
					hsync-len = <0x1f4>;
					hback-porch = <0x1e>;
					vfront-porch = <0x28>;
					vsync-len = <0x14>;
					vback-porch = <0x28>;
					hsync-active = <0x00>;
					vsync-active = <0x00>;
					de-active = <0x00>;
					pixelclk-active = <0x00>;
					phandle = <0x71>;
				};

				timing-5120 {
					clock-frequency = <0x4c4b400>;
					hactive = <0x1400>;
					vactive = <0x5a0>;
					hfront-porch = <0x5dc>;
					hsync-len = <0x1f4>;
					hback-porch = <0x1e>;
					vfront-porch = <0x28>;
					vsync-len = <0x14>;
					vback-porch = <0x28>;
					hsync-active = <0x00>;
					vsync-active = <0x00>;
					de-active = <0x00>;
					pixelclk-active = <0x00>;
					phandle = <0x40>;
				};

				timing-4k {
					clock-frequency = <0xee6b280>;
					hactive = <0xf00>;
					vactive = <0x870>;
					hfront-porch = <0x5dc>;
					hsync-len = <0x1f4>;
					hback-porch = <0x1e>;
					vfront-porch = <0x28>;
					vsync-len = <0x14>;
					vback-porch = <0x28>;
					hsync-active = <0x00>;
					vsync-active = <0x00>;
					de-active = <0x00>;
					pixelclk-active = <0x00>;
					phandle = <0x72>;
				};

				timing-4096 {
					clock-frequency = <0xb532b80>;
					hactive = <0x1000>;
					vactive = <0x800>;
					hfront-porch = <0x5dc>;
					hsync-len = <0x1f4>;
					hback-porch = <0x1e>;
					vfront-porch = <0x28>;
					vsync-len = <0x14>;
					vback-porch = <0x28>;
					hsync-active = <0x00>;
					vsync-active = <0x00>;
					de-active = <0x00>;
					pixelclk-active = <0x00>;
					phandle = <0x73>;
				};

				timing-1920x3-1080 {
					clock-frequency = <0xee6b280>;
					hactive = <0x1680>;
					vactive = <0x438>;
					hfront-porch = <0x5dc>;
					hsync-len = <0x46>;
					hback-porch = <0x1e>;
					vfront-porch = <0x28>;
					vsync-len = <0x14>;
					vback-porch = <0x28>;
					hsync-active = <0x00>;
					vsync-active = <0x00>;
					de-active = <0x00>;
					pixelclk-active = <0x00>;
					phandle = <0x74>;
				};
			};
		};
	};

	dsi@ffb30000 {
		compatible = "rockchip,rk1808-mipi-dsi";
		reg = <0x00 0xffb30000 0x00 0x500>;
		interrupts = <0x00 0x3b 0x04>;
		clocks = <0x02 0xfb 0x3e>;
		clock-names = "pclk\0hs_clk";
		resets = <0x02 0x68>;
		reset-names = "apb";
		phys = <0x3e>;
		phy-names = "mipi_dphy";
		power-domains = <0x0e 0x08>;
		rockchip,grf = <0x15>;
		#address-cells = <0x01>;
		#size-cells = <0x00>;
		status = "disabled";
		phandle = <0x75>;

		ports {

			port {

				endpoint {
					remote-endpoint = <0x41>;
					phandle = <0x3a>;
				};
			};
		};
	};

	vop@ffb40000 {
		compatible = "rockchip,rk1808-vop-raw";
		reg = <0x00 0xffb40000 0x00 0x500>;
		reg-names = "regs";
		interrupts = <0x00 0x3e 0x04>;
		clocks = <0x02 0x9f 0x02 0x0a 0x02 0xca>;
		clock-names = "aclk_vop\0dclk_vop\0hclk_vop";
		power-domains = <0x0e 0x08>;
		iommus = <0x42>;
		status = "okay";
		assigned-clocks = <0x02 0x0a>;
		assigned-clock-rates = <0x4c4b400>;
		phandle = <0x76>;

		port {
			#address-cells = <0x01>;
			#size-cells = <0x00>;
			phandle = <0x51>;

			endpoint@0 {
				reg = <0x00>;
				remote-endpoint = <0x43>;
				phandle = <0x3f>;
			};
		};
	};

	iommu@ffb40f00 {
		compatible = "rockchip,iommu";
		reg = <0x00 0xffb40f00 0x00 0x100>;
		interrupts = <0x00 0x3e 0x04>;
		interrupt-names = "vopr_mmu";
		clocks = <0x02 0x9f 0x02 0xca>;
		clock-names = "aclk\0hclk";
		power-domains = <0x0e 0x08>;
		#iommu-cells = <0x00>;
		status = "okay";
		phandle = <0x42>;
	};

	rkisp1@ffb50000 {
		compatible = "rockchip,rk1808-rkisp1";
		reg = <0x00 0xffb50000 0x00 0x8000>;
		interrupts = <0x00 0x61 0x04 0x00 0x60 0x04 0x00 0x5f 0x04>;
		interrupt-names = "isp_irq\0mi_irq\0mipi_irq";
		clocks = <0x02 0xa2 0x02 0xcd 0x02 0x1e 0x02 0x0c>;
		clock-names = "aclk_isp\0hclk_isp\0clk_isp\0pclk_isp";
		power-domains = <0x0e 0x08>;
		iommus = <0x44>;
		rockchip,grf = <0x15>;
		status = "disabled";
		phandle = <0x77>;
	};

	iommu@ffb58000 {
		compatible = "rockchip,iommu";
		reg = <0x00 0xffb58000 0x00 0x100>;
		interrupts = <0x00 0x61 0x04>;
		interrupt-names = "isp_mmu";
		clocks = <0x02 0xa2 0x02 0xcd 0x02 0x1e>;
		clock-names = "aclk\0hclk\0sclk";
		power-domains = <0x0e 0x08>;
		rk_iommu,disable_reset_quirk;
		#iommu-cells = <0x00>;
		status = "okay";
		phandle = <0x44>;
	};

	vpu_service@ffb80000 {
		compatible = "rockchip,vpu_service";
		reg = <0x00 0xffb80000 0x00 0x800>;
		interrupts = <0x00 0x5d 0x04 0x00 0x5e 0x04>;
		interrupt-names = "irq_enc\0irq_dec";
		clocks = <0x02 0x93 0x02 0xc8>;
		clock-names = "aclk_vcodec\0hclk_vcodec";
		power-domains = <0x0e 0x07>;
		resets = <0x02 0x5e 0x02 0x5f>;
		reset-names = "video_a\0video_h";
		iommus = <0x45>;
		iommu_enabled = <0x01>;
		allocator = <0x01>;
		status = "okay";
		phandle = <0x78>;
	};

	iommu@ffb80800 {
		compatible = "rockchip,iommu";
		reg = <0x00 0xffb80800 0x00 0x100>;
		interrupts = <0x00 0x5c 0x04>;
		interrupt-names = "vpu_mmu";
		clocks = <0x02 0x93 0x02 0xc8>;
		clock-names = "aclk\0hclk";
		power-domains = <0x0e 0x07>;
		#iommu-cells = <0x00>;
		status = "okay";
		phandle = <0x45>;
	};

	npu@ffbc0000 {
		compatible = "rockchip,npu";
		reg = <0x00 0xffbc0000 0x00 0x1000>;
		clocks = <0x02 0x16 0x02 0x94 0x02 0xc7>;
		clock-names = "sclk_npu\0aclk_npu\0hclk_npu";
		assigned-clocks = <0x02 0x16>;
		assigned-clock-rates = <0x2faf0800>;
		interrupts = <0x00 0x2b 0x04>;
		power-domains = <0x0e 0x04>;
		operating-points-v2 = <0x46>;
		#cooling-cells = <0x02>;
		status = "okay";
		npu-supply = <0x47>;
		phandle = <0x1b>;

		power-model {
			compatible = "simple-power-model";
			static-coefficient = <0x539ce>;
			dynamic-coefficient = <0xc08>;
			ts = <0x7d00 0x125c 0xffffffb0 0x02>;
			thermal-zone = "soc-thermal";
			phandle = <0x79>;
		};
	};

	npu-opp-table {
		compatible = "operating-points-v2";
		rockchip,max-volt = <0xd6d80>;
		rockchip,evb-irdrop = <0x927c>;
		rockchip,pvtm-voltage-sel = <0x00 0x10d88 0x00 0x10d89 0x12110 0x01 0x12111 0x1869f 0x02>;
		rockchip,pvtm-freq = <0x30d40>;
		rockchip,pvtm-volt = "\0\f5";
		rockchip,pvtm-ch = <0x02 0x00>;
		rockchip,pvtm-sample-time = <0x3e8>;
		rockchip,pvtm-number = <0x0a>;
		rockchip,pvtm-error = <0x3e8>;
		rockchip,pvtm-ref-temp = <0x19>;
		rockchip,pvtm-temp-prop = <0xffffffec 0xffffffe6>;
		rockchip,thermal-zone = "soc-thermal";
		nvmem-cells = <0x48>;
		nvmem-cell-names = "leakage";
		phandle = <0x46>;

		opp-200000000 {
			opp-hz = <0x00 0xbebc200>;
			opp-microvolt = <0xb71b0 0xb71b0 0xd6d80>;
		};

		opp-297000000 {
			opp-hz = <0x00 0x11b3dc40>;
			opp-microvolt = <0xb71b0 0xb71b0 0xd6d80>;
		};

		opp-400000000 {
			opp-hz = <0x00 0x17d78400>;
			opp-microvolt = <0xb71b0 0xb71b0 0xd6d80>;
		};

		opp-594000000 {
			opp-hz = <0x00 0x2367b880>;
			opp-microvolt = <0xb71b0 0xb71b0 0xd6d80>;
		};

		opp-792000000 {
			opp-hz = <0x00 0x2f34f600>;
			opp-microvolt = <0xc96a8 0xc96a8 0xd6d80>;
			opp-microvolt-L0 = <0xc96a8 0xc96a8 0xd6d80>;
			opp-microvolt-L1 = <0xc3500 0xc3500 0xd6d80>;
			opp-microvolt-L2 = <0xbd358 0xbd358 0xd6d80>;
		};
	};

	pinctrl {
		compatible = "rockchip,rk1808-pinctrl";
		rockchip,grf = <0x15>;
		rockchip,pmu = <0x10>;
		#address-cells = <0x02>;
		#size-cells = <0x02>;
		ranges;
		phandle = <0x7a>;

		gpio0@ff4c0000 {
			compatible = "rockchip,gpio-bank";
			reg = <0x00 0xff4c0000 0x00 0x100>;
			interrupts = <0x00 0x03 0x04>;
			clocks = <0x02 0x124 0x02 0x6b>;
			gpio-controller;
			#gpio-cells = <0x02>;
			interrupt-controller;
			#interrupt-cells = <0x02>;
			phandle = <0x2d>;
		};

		gpio1@ff690000 {
			compatible = "rockchip,gpio-bank";
			reg = <0x00 0xff690000 0x00 0x100>;
			interrupts = <0x00 0x04 0x04>;
			clocks = <0x02 0x114 0x02 0x50>;
			gpio-controller;
			#gpio-cells = <0x02>;
			interrupt-controller;
			#interrupt-cells = <0x02>;
			phandle = <0x7b>;
		};

		gpio2@ff6a0000 {
			compatible = "rockchip,gpio-bank";
			reg = <0x00 0xff6a0000 0x00 0x100>;
			interrupts = <0x00 0x05 0x04>;
			clocks = <0x02 0x115 0x02 0x51>;
			gpio-controller;
			#gpio-cells = <0x02>;
			interrupt-controller;
			#interrupt-cells = <0x02>;
			phandle = <0x7c>;
		};

		gpio3@ff6b0000 {
			compatible = "rockchip,gpio-bank";
			reg = <0x00 0xff6b0000 0x00 0x100>;
			interrupts = <0x00 0x06 0x04>;
			clocks = <0x02 0x116 0x02 0x52>;
			gpio-controller;
			#gpio-cells = <0x02>;
			interrupt-controller;
			#interrupt-cells = <0x02>;
			phandle = <0x7d>;
		};

		gpio4@ff6c0000 {
			compatible = "rockchip,gpio-bank";
			reg = <0x00 0xff6c0000 0x00 0x100>;
			interrupts = <0x00 0x52 0x04>;
			clocks = <0x02 0x117 0x02 0x53>;
			gpio-controller;
			#gpio-cells = <0x02>;
			interrupt-controller;
			#interrupt-cells = <0x02>;
			phandle = <0x7e>;
		};

		pcfg-pull-down {
			bias-pull-down;
			phandle = <0x4e>;
		};

		pcfg-pull-none {
			bias-disable;
			phandle = <0x49>;
		};

		pcfg-pull-up-2ma {
			bias-pull-up;
			drive-strength = <0x02>;
			phandle = <0x4b>;
		};

		pcfg-pull-none-smt {
			bias-disable;
			input-schmitt-enable;
			phandle = <0x7f>;
		};

		pcfg-pull-none-2ma-smt {
			bias-disable;
			drive-strength = <0x02>;
			input-schmitt-enable;
			phandle = <0x4a>;
		};

		pcfg-output-high {
			output-high;
			phandle = <0x4d>;
		};

		pcfg-input-smt {
			input-enable;
			input-schmitt-enable;
			phandle = <0x4c>;
		};

		cif-m0 {

			cif-clkout-m0 {
				rockchip,pins = <0x02 0x0f 0x01 0x49>;
				phandle = <0x80>;
			};

			cif-d12d15-m0 {
				rockchip,pins = <0x02 0x00 0x01 0x49 0x02 0x01 0x01 0x49 0x02 0x02 0x01 0x49 0x02 0x03 0x01 0x49>;
				phandle = <0x81>;
			};

			cif-d10d11-m0 {
				rockchip,pins = <0x02 0x12 0x01 0x49 0x02 0x13 0x01 0x49>;
				phandle = <0x82>;
			};

			cif-d2d9-m0 {
				rockchip,pins = <0x02 0x04 0x01 0x49 0x02 0x05 0x01 0x49 0x02 0x06 0x01 0x49 0x02 0x07 0x01 0x49 0x02 0x08 0x01 0x49 0x02 0x09 0x01 0x49 0x02 0x0a 0x01 0x49 0x02 0x0b 0x01 0x49 0x02 0x0c 0x01 0x49 0x02 0x0d 0x01 0x49 0x02 0x0e 0x01 0x49>;
				phandle = <0x83>;
			};

			cif-d0d1-m0 {
				rockchip,pins = <0x02 0x10 0x01 0x49 0x02 0x11 0x01 0x49>;
				phandle = <0x84>;
			};
		};

		i2c0 {

			i2c0-xfer {
				rockchip,pins = <0x00 0x09 0x01 0x4a 0x00 0x08 0x01 0x4a>;
				phandle = <0x29>;
			};
		};

		i2c1 {

			i2c1-xfer {
				rockchip,pins = <0x00 0x11 0x01 0x4a 0x00 0x10 0x01 0x4a>;
				phandle = <0x2a>;
			};
		};

		i2c3 {

			i2c3-xfer {
				rockchip,pins = <0x02 0x19 0x01 0x4a 0x02 0x18 0x01 0x4a>;
				phandle = <0x2f>;
			};
		};

		pciusb {

			pciusb-pins {
				rockchip,pins = <0x04 0x0c 0x03 0x49 0x04 0x0d 0x03 0x49 0x04 0x0e 0x03 0x49 0x04 0x0f 0x03 0x49 0x04 0x10 0x03 0x49 0x04 0x11 0x03 0x49 0x04 0x12 0x03 0x49 0x04 0x13 0x03 0x49>;
				phandle = <0x85>;
			};

			pcie-clkreq {
				rockchip,pins = <0x00 0x16 0x01 0x49>;
				phandle = <0x0d>;
			};
		};

		uart2 {

			uart2m0-xfer {
				rockchip,pins = <0x04 0x03 0x02 0x4b 0x04 0x02 0x02 0x4b>;
				phandle = <0x31>;
			};

			uart2m1-xfer {
				rockchip,pins = <0x02 0x19 0x02 0x4b 0x02 0x18 0x02 0x4b>;
				phandle = <0x86>;
			};

			uart2m2-xfer {
				rockchip,pins = <0x03 0x04 0x02 0x4b 0x03 0x03 0x02 0x4b>;
				phandle = <0x87>;
			};
		};

		tsadc {

			tsadc-otp-gpio {
				rockchip,pins = <0x00 0x06 0x00 0x49>;
				phandle = <0x1c>;
			};

			tsadc-otp-out {
				rockchip,pins = <0x00 0x06 0x02 0x49>;
				phandle = <0x1d>;
			};
		};

		xin32k {

			clkin-32k {
				rockchip,pins = <0x00 0x12 0x01 0x4c>;
				phandle = <0x0a>;
			};

			clkout-32k {
				rockchip,pins = <0x00 0x12 0x01 0x4d>;
				phandle = <0x88>;
			};
		};

		vsel-gpio {
			rockchip,pins = <0x00 0x16 0x00 0x4e>;
			phandle = <0x2c>;
		};

		pwr-key {
			rockchip,pins = <0x00 0x08 0x00 0x49>;
			phandle = <0x4f>;
		};
	};

	chosen {
		bootargs = "earlycon=uart8250,mmio32,0xff550000 console=ttyFIQ0 init=/init swiotlb=1 kpti=0";
	};

	reserved-memory {
		#address-cells = <0x02>;
		#size-cells = <0x02>;
		ranges;

		dma_trans@3c000000 {
			reg = <0x00 0x3c000000 0x00 0x4000000>;
			phandle = <0x11>;
		};
	};

	gpio-keys {
		compatible = "gpio-keys";
		pinctrl-names = "default";
		pinctrl-0 = <0x4f>;
		phandle = <0x89>;

		power {
			gpios = <0x2d 0x08 0x00>;
			label = "GPIO Power";
			linux,code = <0x74>;
			wakeup-source;
		};
	};

	fiq-debugger {
		compatible = "rockchip,fiq-debugger";
		rockchip,serial-id = <0x02>;
		rockchip,wake-irq = <0x00>;
		rockchip,irq-mode-enable = <0x00>;
		rockchip,baudrate = <0x16e360>;
		interrupts = <0x00 0xf2 0x04>;
		pinctrl-names = "default";
		pinctrl-0 = <0x31>;
		status = "okay";
	};

	vdd-cpu {
		compatible = "regulator-fixed";
		regulator-name = "vdd_cpu";
		regulator-always-on;
		regulator-boot-on;
		regulator-min-microvolt = <0xcf850>;
		regulator-max-microvolt = <0xcf850>;
		phandle = <0x04>;
	};

	vcc5v0-sys {
		compatible = "regulator-fixed";
		regulator-name = "vcc5v0_sys";
		regulator-always-on;
		regulator-boot-on;
		regulator-min-microvolt = <0x4c4b40>;
		regulator-max-microvolt = <0x4c4b40>;
		phandle = <0x2b>;
	};

	display-subsystem {
		compatible = "rockchip,display-subsystem";
		ports = <0x50 0x51>;
		status = "okay";
		phandle = <0x8a>;

		route {

			route-csi {
				status = "disabled";
				connect = <0x3f>;
				phandle = <0x8b>;
			};

			route-dsi {
				status = "disabled";
				connect = <0x41>;
				phandle = <0x8c>;
			};

			route-rgb {
				status = "disabled";
				connect = <0x14>;
				phandle = <0x8d>;
			};
		};
	};

	__symbols__ {
		ddr_timing = "/ddr_timing";
		cpu0 = "/cpus/cpu@0";
		cpu1 = "/cpus/cpu@1";
		cpu0_opp_table = "/cpu0-opp-table";
		rockchip_suspend = "/rockchip-suspend";
		xin24m = "/xin24m";
		xin32k = "/xin32k";
		pcie0 = "/pcie@fc400000";
		usbdrd3 = "/usb";
		usbdrd_dwc3 = "/usb/dwc3@fd000000";
		grf = "/syscon@fe000000";
		npu_pvtm = "/syscon@fe000000/npu-pvtm";
		rgb = "/syscon@fe000000/rgb";
		rgb_in_vop_lite = "/syscon@fe000000/rgb/ports/port@0/endpoint";
		usb2phy_grf = "/syscon@fe010000";
		u2phy = "/syscon@fe010000/usb2-phy@100";
		u2phy_host = "/syscon@fe010000/usb2-phy@100/host-port";
		u2phy_otg = "/syscon@fe010000/usb2-phy@100/otg-port";
		combphy_grf = "/syscon@fe018000";
		pmugrf = "/syscon@fe020000";
		pmu_pvtm = "/syscon@fe020000/pmu-pvtm";
		usb_pcie_grf = "/syscon@fe040000";
		coregrf = "/syscon@fe050000";
		pvtm = "/syscon@fe050000/pvtm";
		qos_npu = "/qos@fe850000";
		qos_pcie = "/qos@fe880000";
		qos_usb2 = "/qos@fe890000";
		qos_usb3 = "/qos@fe890080";
		qos_isp = "/qos@fe8a0000";
		qos_rga_rd = "/qos@fe8a0080";
		qos_rga_wr = "/qos@fe8a0100";
		qos_cif = "/qos@fe8a0180";
		qos_vop_raw = "/qos@fe8b0000";
		qos_vop_lite = "/qos@fe8b0080";
		qos_vpu = "/qos@fe8c0000";
		gic = "/interrupt-controller@ff100000";
		its = "/interrupt-controller@ff100000/interrupt-controller@ff120000";
		efuse = "/efuse@ff260000";
		efuse_id = "/efuse@ff260000/id@7";
		cpu_leakage = "/efuse@ff260000/cpu-leakage@17";
		logic_leakage = "/efuse@ff260000/logic-leakage@18";
		npu_leakage = "/efuse@ff260000/npu-leakage@19";
		efuse_cpu_version = "/efuse@ff260000/cpu-version@1c";
		cru = "/clock-controller@ff350000";
		mipi_dphy_rx = "/mipi-dphy-rx@ff360000";
		mipi_in_ucam = "/mipi-dphy-rx@ff360000/ports/port@0/endpoint@1";
		dphy_rx_out = "/mipi-dphy-rx@ff360000/ports/port@1/endpoint@0";
		mipi_dphy = "/mipi-dphy@ff370000";
		combphy = "/phy@ff380000";
		thermal_zones = "/thermal-zones";
		soc_thermal = "/thermal-zones/soc-thermal";
		threshold = "/thermal-zones/soc-thermal/trips/trip-point-0";
		target = "/thermal-zones/soc-thermal/trips/trip-point-1";
		soc_crit = "/thermal-zones/soc-thermal/trips/soc-crit";
		tsadc = "/tsadc@ff3a0000";
		pmu = "/power-management@ff3e0000";
		power = "/power-management@ff3e0000/power-controller";
		i2c0 = "/i2c@ff410000";
		dmac = "/dmac@ff4e0000";
		i2c1 = "/i2c@ff500000";
		vdd_npu = "/i2c@ff500000/tcs452x@1c";
		vcamera_out = "/i2c@ff500000/vcamera@30/port/endpoint";
		i2c3 = "/i2c@ff508000";
		uart2 = "/serial@ff550000";
		dcf = "/dcf@ff640000";
		rktimer = "/rktimer@ff700000";
		dfi = "/dfi@ff9c0000";
		dmc = "/dmc";
		dmc_opp_table = "/dmc-opp-table";
		rk_rga = "/rk_rga@ffaf0000";
		cif = "/cif@ffae0000";
		cif_in = "/cif@ffae0000/port/endpoint@0";
		cif_mmu = "/iommu@ffae0800";
		vop_lite = "/vop@ffb00000";
		vop_lite_out = "/vop@ffb00000/port";
		vop_lite_out_dsi = "/vop@ffb00000/port/endpoint@0";
		vop_lite_out_rgb = "/vop@ffb00000/port/endpoint@1";
		vopl_mmu = "/iommu@ffb00f00";
		mipi_csi2 = "/mipi-csi2@ffb10000";
		csi2_in = "/mipi-csi2@ffb10000/ports/port@0/endpoint@1";
		csi2_out = "/mipi-csi2@ffb10000/ports/port@1/endpoint@0";
		csi_tx = "/csi@ffb20000";
		csi_in_vop_raw = "/csi@ffb20000/ports/port/endpoint";
		timing_1280x3_720 = "/csi@ffb20000/panel@0/display-timings/timing-1280x3-720";
		timing_5120 = "/csi@ffb20000/panel@0/display-timings/timing-5120";
		timing_4k = "/csi@ffb20000/panel@0/display-timings/timing-4k";
		timing_4096 = "/csi@ffb20000/panel@0/display-timings/timing-4096";
		timing_1920x3_1080 = "/csi@ffb20000/panel@0/display-timings/timing-1920x3-1080";
		dsi = "/dsi@ffb30000";
		dsi_in_vop_lite = "/dsi@ffb30000/ports/port/endpoint";
		vop_raw = "/vop@ffb40000";
		vop_raw_out = "/vop@ffb40000/port";
		vop_raw_out_csi = "/vop@ffb40000/port/endpoint@0";
		vopr_mmu = "/iommu@ffb40f00";
		rkisp1 = "/rkisp1@ffb50000";
		isp_mmu = "/iommu@ffb58000";
		vpu_service = "/vpu_service@ffb80000";
		vpu_mmu = "/iommu@ffb80800";
		npu = "/npu@ffbc0000";
		npu_power_model = "/npu@ffbc0000/power-model";
		npu_opp_table = "/npu-opp-table";
		pinctrl = "/pinctrl";
		gpio0 = "/pinctrl/gpio0@ff4c0000";
		gpio1 = "/pinctrl/gpio1@ff690000";
		gpio2 = "/pinctrl/gpio2@ff6a0000";
		gpio3 = "/pinctrl/gpio3@ff6b0000";
		gpio4 = "/pinctrl/gpio4@ff6c0000";
		pcfg_pull_down = "/pinctrl/pcfg-pull-down";
		pcfg_pull_none = "/pinctrl/pcfg-pull-none";
		pcfg_pull_up_2ma = "/pinctrl/pcfg-pull-up-2ma";
		pcfg_pull_none_smt = "/pinctrl/pcfg-pull-none-smt";
		pcfg_pull_none_2ma_smt = "/pinctrl/pcfg-pull-none-2ma-smt";
		pcfg_output_high = "/pinctrl/pcfg-output-high";
		pcfg_input_smt = "/pinctrl/pcfg-input-smt";
		cif_clkout_m0 = "/pinctrl/cif-m0/cif-clkout-m0";
		cif_d12d15_m0 = "/pinctrl/cif-m0/cif-d12d15-m0";
		cif_d10d11_m0 = "/pinctrl/cif-m0/cif-d10d11-m0";
		cif_d2d9_m0 = "/pinctrl/cif-m0/cif-d2d9-m0";
		cif_d0d1_m0 = "/pinctrl/cif-m0/cif-d0d1-m0";
		i2c0_xfer = "/pinctrl/i2c0/i2c0-xfer";
		i2c1_xfer = "/pinctrl/i2c1/i2c1-xfer";
		i2c3_xfer = "/pinctrl/i2c3/i2c3-xfer";
		pciusb_pins = "/pinctrl/pciusb/pciusb-pins";
		pcie_clkreq = "/pinctrl/pciusb/pcie-clkreq";
		uart2m0_xfer = "/pinctrl/uart2/uart2m0-xfer";
		uart2m1_xfer = "/pinctrl/uart2/uart2m1-xfer";
		uart2m2_xfer = "/pinctrl/uart2/uart2m2-xfer";
		tsadc_otp_gpio = "/pinctrl/tsadc/tsadc-otp-gpio";
		tsadc_otp_out = "/pinctrl/tsadc/tsadc-otp-out";
		clkin_32k = "/pinctrl/xin32k/clkin-32k";
		clkout_32k = "/pinctrl/xin32k/clkout-32k";
		vsel_gpio = "/pinctrl/vsel-gpio";
		pwr_key = "/pinctrl/pwr-key";
		dma_trans = "/reserved-memory/dma_trans@3c000000";
		keys = "/gpio-keys";
		vdd_cpu = "/vdd-cpu";
		vcc5v0_sys = "/vcc5v0-sys";
		display_subsystem = "/display-subsystem";
		route_csi = "/display-subsystem/route/route-csi";
		route_dsi = "/display-subsystem/route/route-dsi";
		route_rgb = "/display-subsystem/route/route-rgb";
	};
};
